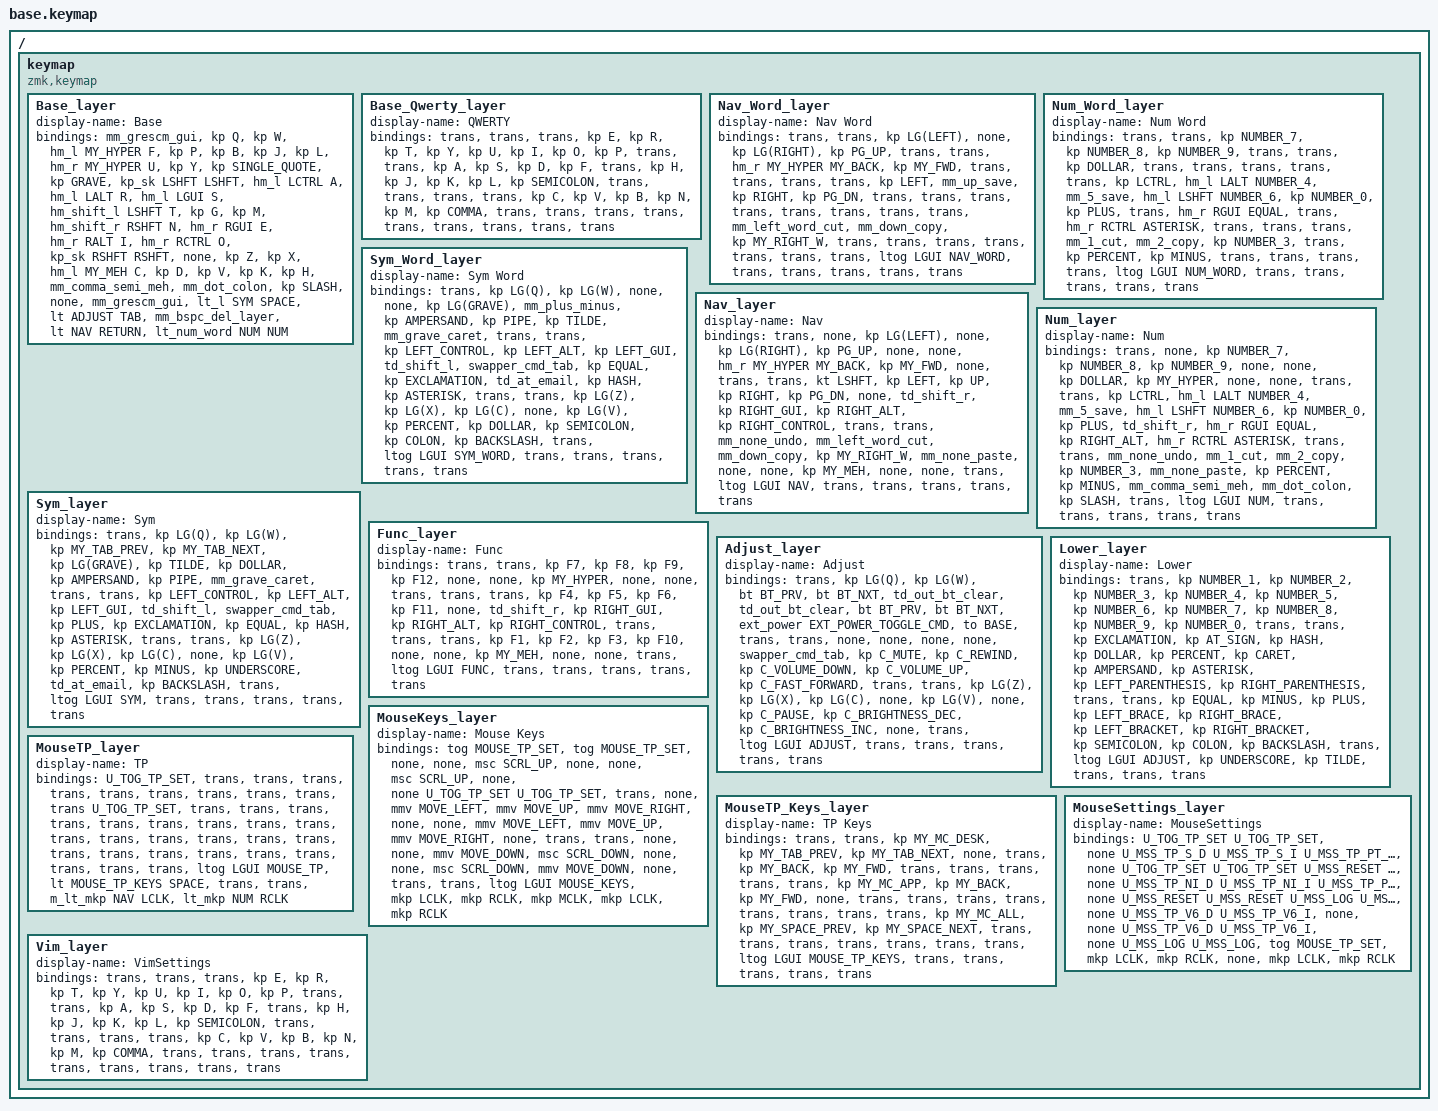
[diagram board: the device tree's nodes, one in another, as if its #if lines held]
/*
 * Copyright (c) 2020 The ZMK Contributors
 *
 * SPDX-License-Identifier: MIT
 */

// Define layer numbers
#define BASE 0
#define BASE_QWERTY 1
#define NAV_WORD 2
#define NUM_WORD 3
#define SYM_WORD 4
#define NAV 5
#define NUM 6
#define SYM 7
#define FUNC 8
#define ADJUST 9
#define LOWER 10
#define MOUSE_KEYS 11
#define MOUSE_TP 12
#define MOUSE_TP_KEYS 13
#define MOUSE_TP_SET 14
#define VIM 15

#ifdef HAS_UROB
  #define HAS_TRI_STATE
  #define HAS_NUM_WORD
#endif

// ZMK includes
#include <behaviors.dtsi>
#include <dt-bindings/zmk/keys.h>
#include <dt-bindings/zmk/bt.h>
#include <dt-bindings/zmk/rgb.h>
#include <dt-bindings/zmk/ext_power.h>


// Personal includes
#include "includes/custom_keycodes.dtsi"
#include "includes/settings.dtsi"
//#include "includes/settings_pd.dtsi"
#include "includes/conditional_layers.dtsi"
#include "includes/macros.dtsi"
#include "includes/combos.dtsi"
#include "includes/behaviours_homerow_mods.dtsi"
#include "includes/behaviours_mod_morph.dtsi"
#include "includes/behaviours_other.dtsi"
#include "includes/mouse_keys.dtsi"
#include "includes/mouse_tp.dtsi"
#include "includes/mouse_tp_badjeff_input_listener.dtsi"


#ifdef HAS_MOUSE_TP
  #define U_TOG_TP_SET &tog MOUSE_TP_SET
#else
  #define U_TOG_TP_SET &none
#endif  // HAS_MOUSE_TP


/ {

  keymap {
    compatible = "zmk,keymap";

    Base_layer {
      display-name = "Base";
      bindings = <
// ╭────────────────────────┬────────────────────────┬────────────────────────┬────────────────────────┬────────────────────────┬────────────────────────╮    ╭────────────────────────┬────────────────────────┬────────────────────────┬───────────────────────┬────────────────────────┬────────────────────────╮
     &mm_grescm_gui           &kp Q                    &kp W                    &hm_l MY_HYPER F         &kp P                    &kp B                         &kp J                    &kp L                    &hm_r MY_HYPER U         &kp Y                    &kp SINGLE_QUOTE         &kp GRAVE
// ├────────────────────────┼────────────────────────┼────────────────────────┼────────────────────────┼────────────────────────┼────────────────────────┤    ├────────────────────────┼────────────────────────┼────────────────────────┼───────────────────────┼────────────────────────┼────────────────────────┤
     &kp_sk LSHFT LSHFT       &hm_l LCTRL A            &hm_l LALT R             &hm_l LGUI S             &hm_shift_l LSHFT T      &kp G                         &kp M                    &hm_shift_r RSHFT N      &hm_r RGUI E             &hm_r RALT I             &hm_r RCTRL O            &kp_sk RSHFT RSHFT
// ├────────────────────────┼────────────────────────┼────────────────────────┼────────────────────────┼────────────────────────┼────────────────────────┤    ├────────────────────────┼────────────────────────┼────────────────────────┼───────────────────────┼────────────────────────┼────────────────────────┤
     &none                    &kp Z                    &kp X                    &hm_l MY_MEH C           &kp D                    &kp V                         &kp K                    &kp H                    &mm_comma_semi_meh       &mm_dot_colon            &kp SLASH                &none
// ╰────────────────────────┴────────────────────────┴────────────────────────┴────────────────────────┼────────────────────────┼────────────────────────┤    ├────────────────────────┼────────────────────────┼────────────────────────┼───────────────────────┼────────────────────────┼────────────────────────╯
                                                                                &mm_grescm_gui           &lt_l SYM SPACE          &lt ADJUST TAB                &mm_bspc_del_layer       &lt NAV RETURN           &lt_num_word NUM NUM
//                                                                            ╰────────────────────────┴────────────────────────┴────────────────────────╯    ╰────────────────────────┴────────────────────────┴────────────────────────╯

      >;
     //  sensor-bindings = <&inc_dec_kp C_VOL_DN C_VOL_UP &inc_dec_kp C_PREV C_NEXT>;
    };

    Base_Qwerty_layer {
      display-name = "QWERTY";
      bindings = <
// ╭────────────────────────┬────────────────────────┬────────────────────────┬────────────────────────┬────────────────────────┬────────────────────────╮    ╭────────────────────────┬────────────────────────┬────────────────────────┬────────────────────────┬────────────────────────┬────────────────────────╮
     &trans                   &trans                   &trans                   &kp E                    &kp R                    &kp T                         &kp Y                    &kp U                    &kp I                    &kp O                    &kp P                     &trans
// ├────────────────────────┼────────────────────────┼────────────────────────┼────────────────────────┼────────────────────────┼────────────────────────┤    ├────────────────────────┼────────────────────────┼────────────────────────┼────────────────────────┼────────────────────────┼────────────────────────┤
     &trans                   &kp A                    &kp S                    &kp D                    &kp F                    &trans                        &kp H                    &kp J                    &kp K                    &kp L                    &kp SEMICOLON             &trans
// ├────────────────────────┼────────────────────────┼────────────────────────┼────────────────────────┼────────────────────────┼────────────────────────┤    ├────────────────────────┼────────────────────────┼────────────────────────┼────────────────────────┼────────────────────────┼────────────────────────┤
     &trans                   &trans                   &trans                   &kp C                    &kp V                    &kp B                         &kp N                    &kp M                    &kp COMMA                &trans                   &trans                    &trans
// ╰────────────────────────┴────────────────────────┴────────────────────────┴────────────────────────┼────────────────────────┼────────────────────────┤    ├────────────────────────┼────────────────────────┼────────────────────────┼────────────────────────┴────────────────────────┼────────────────────────╯
                                                                                &trans                   &trans                   &trans                        &trans                   &trans                   &trans
//                                                                            ╰────────────────────────┴────────────────────────┴────────────────────────╯    ╰────────────────────────┴────────────────────────┴────────────────────────╯
      >;
    };

    Nav_Word_layer {
      display-name = "Nav Word";
      bindings = <
// ╭────────────────────────┬────────────────────────┬────────────────────────┬────────────────────────┬────────────────────────┬────────────────────────╮    ╭────────────────────────┬────────────────────────┬────────────────────────┬────────────────────────┬────────────────────────┬────────────────────────╮
     &trans                   &trans                   &kp LG(LEFT)             &none                    &kp LG(RIGHT)            &kp PG_UP                     &trans                   &trans                   &hm_r MY_HYPER MY_BACK   &kp MY_FWD               &trans                    &trans
// ├────────────────────────┼────────────────────────┼────────────────────────┼────────────────────────┼────────────────────────┼────────────────────────┤    ├────────────────────────┼────────────────────────┼────────────────────────┼────────────────────────┼────────────────────────┼────────────────────────┤
     &trans                   &trans                   &kp LEFT                 &mm_up_save              &kp RIGHT                &kp PG_DN                     &trans                   &trans                   &trans                   &trans                   &trans                    &trans
// ├────────────────────────┼────────────────────────┼────────────────────────┼────────────────────────┼────────────────────────┼────────────────────────┤    ├────────────────────────┼────────────────────────┼────────────────────────┼────────────────────────┼────────────────────────┼────────────────────────┤
     &trans                   &trans                   &mm_left_word_cut        &mm_down_copy            &kp MY_RIGHT_W           &trans                        &trans                   &trans                   &trans                   &trans                   &trans                    &trans
// ╰────────────────────────┴────────────────────────┴────────────────────────┴────────────────────────┼────────────────────────┼────────────────────────┤    ├────────────────────────┼────────────────────────┼────────────────────────┼────────────────────────┴────────────────────────┼────────────────────────╯
                                                                                &ltog LGUI NAV_WORD      &trans                   &trans                        &trans                   &trans                   &trans
//                                                                            ╰────────────────────────┴────────────────────────┴────────────────────────╯    ╰────────────────────────┴────────────────────────┴────────────────────────╯
      >;
     //  sensor-bindings = <&inc_dec_kp C_BRI_DN C_BRI_UP &inc_dec_kp LEFT RIGHT>;
    };

    Num_Word_layer {
      display-name = "Num Word";
      bindings = <
// ╭────────────────────────┬────────────────────────┬────────────────────────┬────────────────────────┬────────────────────────┬────────────────────────╮    ╭────────────────────────┬────────────────────────┬────────────────────────┬────────────────────────┬────────────────────────┬────────────────────────╮
     &trans                   &trans                   &kp NUMBER_7             &kp NUMBER_8             &kp NUMBER_9             &trans                        &trans                   &kp DOLLAR               &trans                   &trans                   &trans                    &trans
// ├────────────────────────┼────────────────────────┼────────────────────────┼────────────────────────┼────────────────────────┼────────────────────────┤    ├────────────────────────┼────────────────────────┼────────────────────────┼────────────────────────┼────────────────────────┼────────────────────────┤
     &trans                   &kp LCTRL                &hm_l LALT NUMBER_4      &mm_5_save               &hm_l LSHFT NUMBER_6     &kp NUMBER_0                  &kp PLUS                 &trans                   &hm_r RGUI EQUAL         &trans                   &hm_r RCTRL ASTERISK      &trans
// ├────────────────────────┼────────────────────────┼────────────────────────┼────────────────────────┼────────────────────────┼────────────────────────┤    ├────────────────────────┼────────────────────────┼────────────────────────┼────────────────────────┼────────────────────────┼────────────────────────┤
     &trans                   &trans                   &mm_1_cut                &mm_2_copy               &kp NUMBER_3             &trans                        &kp PERCENT              &kp MINUS                &trans                   &trans                   &trans                    &trans
// ╰────────────────────────┴────────────────────────┴────────────────────────┴────────────────────────┼────────────────────────┼────────────────────────┤    ├────────────────────────┼────────────────────────┼────────────────────────┼────────────────────────┴────────────────────────┼────────────────────────╯
                                                                                &ltog LGUI NUM_WORD      &trans                   &trans                        &trans                   &trans                   &trans
//                                                                            ╰────────────────────────┴────────────────────────┴────────────────────────╯    ╰────────────────────────┴────────────────────────┴────────────────────────╯
      >;
     //  sensor-bindings = <&inc_dec_kp C_BRI_DN C_BRI_UP &inc_dec_kp LEFT RIGHT>;
    };

    Sym_Word_layer {
      display-name = "Sym Word";
      bindings = <
// ╭────────────────────────┬────────────────────────┬────────────────────────┬────────────────────────┬────────────────────────┬────────────────────────╮    ╭────────────────────────┬────────────────────────┬────────────────────────┬────────────────────────┬────────────────────────┬────────────────────────╮
     &trans                   &kp LG(Q)                &kp LG(W)                &none                    &none                    &kp LG(GRAVE)                 &mm_plus_minus           &kp AMPERSAND            &kp PIPE                 &kp TILDE                &mm_grave_caret           &trans
// ├────────────────────────┼────────────────────────┼────────────────────────┼────────────────────────┼────────────────────────┼────────────────────────┤    ├────────────────────────┼────────────────────────┼────────────────────────┼────────────────────────┼────────────────────────┼────────────────────────┤
     &trans                   &kp LEFT_CONTROL         &kp LEFT_ALT             &kp LEFT_GUI             &td_shift_l              &swapper_cmd_tab              &kp EQUAL                &kp EXCLAMATION          &td_at_email             &kp HASH                 &kp ASTERISK              &trans
// ├────────────────────────┼────────────────────────┼────────────────────────┼────────────────────────┼────────────────────────┼────────────────────────┤    ├────────────────────────┼────────────────────────┼────────────────────────┼────────────────────────┼────────────────────────┼────────────────────────┤
     &trans                   &kp LG(Z)                &kp LG(X)                &kp LG(C)                &none                    &kp LG(V)                     &kp PERCENT              &kp DOLLAR               &kp SEMICOLON            &kp COLON                &kp BACKSLASH             &trans
// ╰────────────────────────┴────────────────────────┴────────────────────────┴────────────────────────┼────────────────────────┼────────────────────────┤    ├────────────────────────┼────────────────────────┼────────────────────────┼────────────────────────┴────────────────────────┼────────────────────────╯
                                                                                &ltog LGUI SYM_WORD      &trans                   &trans                        &trans                   &trans                   &trans
//                                                                            ╰────────────────────────┴────────────────────────┴────────────────────────╯    ╰────────────────────────┴────────────────────────┴────────────────────────╯
      >;
     //  sensor-bindings = <&inc_dec_kp C_BRI_DN C_BRI_UP &inc_dec_kp LEFT RIGHT>;
    };

    Nav_layer {
      display-name = "Nav";
      bindings = <
// ╭────────────────────────┬────────────────────────┬────────────────────────┬────────────────────────┬────────────────────────┬────────────────────────╮    ╭────────────────────────┬────────────────────────┬────────────────────────┬────────────────────────┬────────────────────────┬────────────────────────╮
     &trans                   &none                    &kp LG(LEFT)             &none                    &kp LG(RIGHT)            &kp PG_UP                     &none                    &none                    &hm_r MY_HYPER MY_BACK   &kp MY_FWD               &none                     &trans
// ├────────────────────────┼────────────────────────┼────────────────────────┼────────────────────────┼────────────────────────┼────────────────────────┤    ├────────────────────────┼────────────────────────┼────────────────────────┼────────────────────────┼────────────────────────┼────────────────────────┤
     &trans                   &kt LSHFT                &kp LEFT                 &kp UP                   &kp RIGHT                &kp PG_DN                     &none                    &td_shift_r              &kp RIGHT_GUI            &kp RIGHT_ALT            &kp RIGHT_CONTROL         &trans
// ├────────────────────────┼────────────────────────┼────────────────────────┼────────────────────────┼────────────────────────┼────────────────────────┤    ├────────────────────────┼────────────────────────┼────────────────────────┼────────────────────────┼────────────────────────┼────────────────────────┤
     &trans                   &mm_none_undo            &mm_left_word_cut        &mm_down_copy            &kp MY_RIGHT_W           &mm_none_paste                &none                    &none                    &kp MY_MEH               &none                    &none                     &trans
// ╰────────────────────────┴────────────────────────┴────────────────────────┴────────────────────────┼────────────────────────┼────────────────────────┤    ├────────────────────────┼────────────────────────┼────────────────────────┼────────────────────────┴────────────────────────┼────────────────────────╯
                                                                                &ltog LGUI NAV           &trans                   &trans                        &trans                   &trans                   &trans
//                                                                            ╰────────────────────────┴────────────────────────┴────────────────────────╯    ╰────────────────────────┴────────────────────────┴────────────────────────╯
      >;
     //  sensor-bindings = <&inc_dec_kp C_BRI_DN C_BRI_UP &inc_dec_kp LEFT RIGHT>;
    };

    Num_layer {
      display-name = "Num";
      bindings = <
// ╭────────────────────────┬────────────────────────┬────────────────────────┬────────────────────────┬────────────────────────┬────────────────────────╮    ╭────────────────────────┬────────────────────────┬────────────────────────┬────────────────────────┬────────────────────────┬────────────────────────╮
     &trans                   &none                    &kp NUMBER_7             &kp NUMBER_8             &kp NUMBER_9             &none                         &none                    &kp DOLLAR               &kp MY_HYPER             &none                    &none                     &trans
// ├────────────────────────┼────────────────────────┼────────────────────────┼────────────────────────┼────────────────────────┼────────────────────────┤    ├────────────────────────┼────────────────────────┼────────────────────────┼────────────────────────┼────────────────────────┼────────────────────────┤
     &trans                   &kp LCTRL                &hm_l LALT NUMBER_4      &mm_5_save               &hm_l LSHFT NUMBER_6     &kp NUMBER_0                  &kp PLUS                 &td_shift_r              &hm_r RGUI EQUAL         &kp RIGHT_ALT            &hm_r RCTRL ASTERISK      &trans
// ├────────────────────────┼────────────────────────┼────────────────────────┼────────────────────────┼────────────────────────┼────────────────────────┤    ├────────────────────────┼────────────────────────┼────────────────────────┼────────────────────────┼────────────────────────┼────────────────────────┤
     &trans                   &mm_none_undo            &mm_1_cut                &mm_2_copy               &kp NUMBER_3             &mm_none_paste                &kp PERCENT              &kp MINUS                &mm_comma_semi_meh       &mm_dot_colon            &kp SLASH                 &trans
// ╰────────────────────────┴────────────────────────┴────────────────────────┴────────────────────────┼────────────────────────┼────────────────────────┤    ├────────────────────────┼────────────────────────┼────────────────────────┼────────────────────────┴────────────────────────┼────────────────────────╯
                                                                                &ltog LGUI NUM           &trans                   &trans                        &trans                   &trans                   &trans
//                                                                            ╰────────────────────────┴────────────────────────┴────────────────────────╯    ╰────────────────────────┴────────────────────────┴────────────────────────╯
      >;
     //  sensor-bindings = <&inc_dec_kp C_BRI_DN C_BRI_UP &inc_dec_kp LEFT RIGHT>;
    };

    Sym_layer {
      display-name = "Sym";
      bindings = <
// ╭────────────────────────┬────────────────────────┬────────────────────────┬────────────────────────┬────────────────────────┬────────────────────────╮    ╭────────────────────────┬────────────────────────┬────────────────────────┬────────────────────────┬────────────────────────┬────────────────────────╮
     &trans                   &kp LG(Q)                &kp LG(W)                &kp MY_TAB_PREV          &kp MY_TAB_NEXT          &kp LG(GRAVE)                 &kp TILDE                &kp DOLLAR               &kp AMPERSAND            &kp PIPE                 &mm_grave_caret           &trans
// ├────────────────────────┼────────────────────────┼────────────────────────┼────────────────────────┼────────────────────────┼────────────────────────┤    ├────────────────────────┼────────────────────────┼────────────────────────┼────────────────────────┼────────────────────────┼────────────────────────┤
     &trans                   &kp LEFT_CONTROL         &kp LEFT_ALT             &kp LEFT_GUI             &td_shift_l              &swapper_cmd_tab              &kp PLUS                 &kp EXCLAMATION          &kp EQUAL                &kp HASH                 &kp ASTERISK              &trans
// ├────────────────────────┼────────────────────────┼────────────────────────┼────────────────────────┼────────────────────────┼────────────────────────┤    ├────────────────────────┼────────────────────────┼────────────────────────┼────────────────────────┼────────────────────────┼────────────────────────┤
     &trans                   &kp LG(Z)                &kp LG(X)                &kp LG(C)                &none &kp                LG(V)                         &kp PERCENT              &kp MINUS                &kp UNDERSCORE           &td_at_email             &kp BACKSLASH             &trans
// ╰────────────────────────┴────────────────────────┴────────────────────────┴────────────────────────┼────────────────────────┼────────────────────────┤    ├────────────────────────┼────────────────────────┼────────────────────────┼────────────────────────┴────────────────────────┼────────────────────────╯
                                                                                &ltog LGUI SYM           &trans                   &trans                        &trans                   &trans                   &trans
//                                                                            ╰────────────────────────┴────────────────────────┴────────────────────────╯    ╰────────────────────────┴────────────────────────┴────────────────────────╯
      >;
     //  sensor-bindings = <&inc_dec_kp C_BRI_DN C_BRI_UP &inc_dec_kp LEFT RIGHT>;
    };

    Func_layer {
      display-name = "Func";
      bindings = <
// ╭────────────────────────┬────────────────────────┬────────────────────────┬────────────────────────┬────────────────────────┬────────────────────────╮    ╭────────────────────────┬────────────────────────┬────────────────────────┬────────────────────────┬────────────────────────┬────────────────────────╮
     &trans                   &trans                   &kp F7                   &kp F8                   &kp F9                   &kp F12                       &none                    &none                    &kp MY_HYPER             &none                    &none                     &trans
// ├────────────────────────┼────────────────────────┼────────────────────────┼────────────────────────┼────────────────────────┼────────────────────────┤    ├────────────────────────┼────────────────────────┼────────────────────────┼────────────────────────┼────────────────────────┼────────────────────────┤
     &trans                   &trans                   &kp F4                   &kp F5                   &kp F6                   &kp F11                       &none                    &td_shift_r              &kp RIGHT_GUI            &kp RIGHT_ALT            &kp RIGHT_CONTROL         &trans
// ├────────────────────────┼────────────────────────┼────────────────────────┼────────────────────────┼────────────────────────┼────────────────────────┤    ├────────────────────────┼────────────────────────┼────────────────────────┼────────────────────────┼────────────────────────┼────────────────────────┤
     &trans                   &trans                   &kp F1                   &kp F2                   &kp F3                   &kp F10                       &none                    &none                    &kp MY_MEH               &none                    &none                     &trans
// ╰────────────────────────┴────────────────────────┴────────────────────────┴────────────────────────┼────────────────────────┼────────────────────────┤    ├────────────────────────┼────────────────────────┼────────────────────────┼────────────────────────┴────────────────────────┼────────────────────────╯
                                                                                &ltog LGUI FUNC          &trans                   &trans                        &trans                   &trans                   &trans
//                                                                            ╰────────────────────────┴────────────────────────┴────────────────────────╯    ╰────────────────────────┴────────────────────────┴────────────────────────╯
      >;
     //  sensor-bindings = <&inc_dec_kp C_BRI_DN C_BRI_UP &inc_dec_kp LEFT RIGHT>;
    };

    Adjust_layer {
      display-name = "Adjust";
      bindings = <
// ╭────────────────────────┬────────────────────────┬────────────────────────┬────────────────────────┬────────────────────────┬────────────────────────╮    ╭────────────────────────┬────────────────────────┬────────────────────────┬────────────────────────┬────────────────────────┬────────────────────────╮
     &trans                   &kp LG(Q)                &kp LG(W)                &bt BT_PRV               &bt BT_NXT               &td_out_bt_clear              &td_out_bt_clear         &bt BT_PRV               &bt BT_NXT               &ext_power EXT_POWER_TOGGLE_CMD &to BASE           &trans
// ├────────────────────────┼────────────────────────┼────────────────────────┼────────────────────────┼────────────────────────┼────────────────────────┤    ├────────────────────────┼────────────────────────┼────────────────────────┼────────────────────────┼────────────────────────┼────────────────────────┤
     &trans                   &none                    &none                    &none                    &none                    &swapper_cmd_tab              &kp C_MUTE               &kp C_REWIND             &kp C_VOLUME_DOWN        &kp C_VOLUME_UP          &kp C_FAST_FORWARD        &trans
// ├────────────────────────┼────────────────────────┼────────────────────────┼────────────────────────┼────────────────────────┼────────────────────────┤    ├────────────────────────┼────────────────────────┼────────────────────────┼────────────────────────┼────────────────────────┼────────────────────────┤
     &trans                   &kp LG(Z)                &kp LG(X)                &kp LG(C)                &none                    &kp LG(V)                     &none                    &kp C_PAUSE              &kp C_BRIGHTNESS_DEC     &kp C_BRIGHTNESS_INC     &none                     &trans
// ╰────────────────────────┴────────────────────────┴────────────────────────┴────────────────────────┼────────────────────────┼────────────────────────┤    ├────────────────────────┼────────────────────────┼────────────────────────┼────────────────────────┴────────────────────────┼────────────────────────╯
                                                                                &ltog LGUI ADJUST        &trans                   &trans                        &trans                   &trans                   &trans
//                                                                            ╰────────────────────────┴────────────────────────┴────────────────────────╯    ╰────────────────────────┴────────────────────────┴────────────────────────╯
      >;
     //  sensor-bindings = <&inc_dec_kp C_BRI_DN C_BRI_UP &inc_dec_kp LEFT RIGHT>;
    };

    Lower_layer {
      display-name = "Lower";
      bindings = <
// ╭────────────────────────┬────────────────────────┬────────────────────────┬────────────────────────┬────────────────────────┬────────────────────────╮    ╭────────────────────────┬────────────────────────┬────────────────────────┬────────────────────────┬────────────────────────┬────────────────────────╮
     &trans                   &kp NUMBER_1             &kp NUMBER_2             &kp NUMBER_3             &kp NUMBER_4             &kp NUMBER_5                  &kp NUMBER_6             &kp NUMBER_7             &kp NUMBER_8             &kp NUMBER_9             &kp NUMBER_0              &trans
// ├────────────────────────┼────────────────────────┼────────────────────────┼────────────────────────┼────────────────────────┼────────────────────────┤    ├────────────────────────┼────────────────────────┼────────────────────────┼────────────────────────┼────────────────────────┼────────────────────────┤
     &trans                   &kp EXCLAMATION          &kp AT_SIGN              &kp HASH                 &kp DOLLAR               &kp PERCENT                   &kp CARET                &kp AMPERSAND            &kp ASTERISK             &kp LEFT_PARENTHESIS     &kp RIGHT_PARENTHESIS     &trans
// ├────────────────────────┼────────────────────────┼────────────────────────┼────────────────────────┼────────────────────────┼────────────────────────┤    ├────────────────────────┼────────────────────────┼────────────────────────┼────────────────────────┼────────────────────────┼────────────────────────┤
     &trans                   &kp EQUAL                &kp MINUS                &kp PLUS                 &kp LEFT_BRACE           &kp RIGHT_BRACE               &kp LEFT_BRACKET         &kp RIGHT_BRACKET        &kp SEMICOLON            &kp COLON                &kp BACKSLASH             &trans
// ╰────────────────────────┴────────────────────────┴────────────────────────┴────────────────────────┼────────────────────────┼────────────────────────┤    ├────────────────────────┼────────────────────────┼────────────────────────┼────────────────────────┴────────────────────────┼────────────────────────╯
                                                                                &ltog LGUI ADJUST        &kp UNDERSCORE           &kp TILDE                     &trans                    &trans                  &trans
//                                                                            ╰────────────────────────┴────────────────────────┴────────────────────────╯    ╰────────────────────────┴────────────────────────┴────────────────────────╯
      >;
     //  sensor-bindings = <&inc_dec_kp C_BRI_DN C_BRI_UP &inc_dec_kp LEFT RIGHT>;
    };

#ifdef HAS_MOUSE_KEYS
    MouseKeys_layer {
      display-name = "Mouse Keys";
      bindings = <
// ╭────────────────────────┬────────────────────────┬────────────────────────┬────────────────────────┬────────────────────────┬────────────────────────╮    ╭────────────────────────┬────────────────────────┬────────────────────────┬────────────────────────┬────────────────────────┬────────────────────────╮
     &tog MOUSE_TP_SET        &tog MOUSE_TP_SET        &none                    &none                    &msc SCRL_UP             &none                         &none                    &msc SCRL_UP             &none                    &none                    U_TOG_TP_SET             U_TOG_TP_SET
// ├────────────────────────┼────────────────────────┼────────────────────────┼────────────────────────┼────────────────────────┼────────────────────────┤    ├────────────────────────┼────────────────────────┼────────────────────────┼────────────────────────┼────────────────────────┼────────────────────────┤
     &trans                   &none                    &mmv MOVE_LEFT           &mmv MOVE_UP             &mmv MOVE_RIGHT          &none                         &none                    &mmv MOVE_LEFT           &mmv MOVE_UP             &mmv MOVE_RIGHT          &none                     &trans
// ├────────────────────────┼────────────────────────┼────────────────────────┼────────────────────────┼────────────────────────┼────────────────────────┤    ├────────────────────────┼────────────────────────┼────────────────────────┼────────────────────────┼────────────────────────┼────────────────────────┤
     &trans                   &none                    &none                    &mmv MOVE_DOWN           &msc SCRL_DOWN           &none                         &none                    &msc SCRL_DOWN           &mmv MOVE_DOWN           &none                    &trans                    &trans
// ╰────────────────────────┴────────────────────────┴────────────────────────┴────────────────────────┼────────────────────────┼────────────────────────┤    ├────────────────────────┼────────────────────────┼────────────────────────┼────────────────────────┴────────────────────────┼────────────────────────╯
                                                                                &ltog LGUI MOUSE_KEYS    &mkp LCLK                &mkp RCLK                     &mkp MCLK                &mkp LCLK                &mkp RCLK
//                                                                            ╰────────────────────────┴────────────────────────┴────────────────────────╯    ╰────────────────────────┴────────────────────────┴────────────────────────╯
      >;
     //  sensor-bindings = <&inc_dec_kp C_BRI_DN C_BRI_UP &inc_dec_kp LEFT RIGHT>;
    };
#endif

#ifdef HAS_MOUSE_TP
    MouseTP_layer {
      display-name = "TP";
      bindings = <
// ╭────────────────────────┬────────────────────────┬────────────────────────┬────────────────────────┬────────────────────────┬────────────────────────╮    ╭────────────────────────┬────────────────────────┬────────────────────────┬────────────────────────┬────────────────────────┬────────────────────────╮
     U_TOG_TP_SET             &trans                   &trans                   &trans                   &trans                   &trans                        &trans                   &trans                   &trans                    &trans                   &trans                    U_TOG_TP_SET
// ├────────────────────────┼────────────────────────┼────────────────────────┼────────────────────────┼────────────────────────┼────────────────────────┤    ├────────────────────────┼────────────────────────┼────────────────────────┼────────────────────────┼────────────────────────┼────────────────────────┤
     &trans                   &trans                   &trans                   &trans                   &trans                   &trans                        &trans                   &trans                   &trans                    &trans                   &trans                    &trans
// ├────────────────────────┼────────────────────────┼────────────────────────┼────────────────────────┼────────────────────────┼────────────────────────┤    ├────────────────────────┼────────────────────────┼────────────────────────┼────────────────────────┼────────────────────────┼────────────────────────┤
     &trans                   &trans                   &trans                   &trans                   &trans                   &trans                        &trans                   &trans                   &trans                    &trans                   &trans                    &trans
// ╰────────────────────────┴────────────────────────┴────────────────────────┴────────────────────────┼────────────────────────┼────────────────────────┤    ├────────────────────────┼────────────────────────┼────────────────────────┼────────────────────────┴────────────────────────┼────────────────────────╯
                                                                                &ltog LGUI MOUSE_TP      &lt MOUSE_TP_KEYS SPACE  &trans                        &trans                    &m_lt_mkp NAV LCLK      &lt_mkp NUM RCLK
//                                                                            ╰────────────────────────┴────────────────────────┴────────────────────────╯    ╰────────────────────────┴────────────────────────┴────────────────────────╯
      >;
     //  sensor-bindings = <&inc_dec_kp C_BRI_DN C_BRI_UP &inc_dec_kp LEFT RIGHT>;
    };

    MouseTP_Keys_layer {
      display-name = "TP Keys";
      bindings = <
// ╭────────────────────────┬────────────────────────┬────────────────────────┬────────────────────────┬────────────────────────┬────────────────────────╮    ╭────────────────────────┬────────────────────────┬────────────────────────┬────────────────────────┬────────────────────────┬────────────────────────╮
     &trans                   &trans                   &kp MY_MC_DESK           &kp MY_TAB_PREV          &kp MY_TAB_NEXT          &none                         &trans                   &kp MY_BACK               &kp MY_FWD               &trans                    &trans                  &trans
// ├────────────────────────┼────────────────────────┼────────────────────────┼────────────────────────┼────────────────────────┼────────────────────────┤    ├────────────────────────┼────────────────────────┼────────────────────────┼────────────────────────┼────────────────────────┼────────────────────────┤
     &trans                   &trans                   &kp MY_MC_APP            &kp MY_BACK              &kp MY_FWD               &none                         &trans                   &trans                    &trans                   &trans                    &trans                  &trans
// ├────────────────────────┼────────────────────────┼────────────────────────┼────────────────────────┼────────────────────────┼────────────────────────┤    ├────────────────────────┼────────────────────────┼────────────────────────┼────────────────────────┼────────────────────────┼────────────────────────┤
     &trans                   &trans                   &kp MY_MC_ALL            &kp MY_SPACE_PREV        &kp MY_SPACE_NEXT        &trans                        &trans                   &trans                    &trans                   &trans                    &trans                  &trans
// ╰────────────────────────┴────────────────────────┴────────────────────────┴────────────────────────┼────────────────────────┼────────────────────────┤    ├────────────────────────┼────────────────────────┼────────────────────────┼────────────────────────┴────────────────────────┼────────────────────────╯
                                                                                &ltog LGUI MOUSE_TP_KEYS &trans                   &trans                        &trans                    &trans                   &trans
//                                                                            ╰────────────────────────┴────────────────────────┴────────────────────────╯    ╰────────────────────────┴────────────────────────┴────────────────────────╯
      >;
     //  sensor-bindings = <&inc_dec_kp C_BRI_DN C_BRI_UP &inc_dec_kp LEFT RIGHT>;
    };

    MouseSettings_layer {
      display-name = "MouseSettings";
      bindings = <
// ╭────────────────────────┬────────────────────────┬────────────────────────┬────────────────────────┬────────────────────────┬────────────────────────╮    ╭────────────────────────┬────────────────────────┬────────────────────────┬────────────────────────┬────────────────────────┬────────────────────────╮
     U_TOG_TP_SET             U_TOG_TP_SET             &none                    U_MSS_TP_S_D             U_MSS_TP_S_I             U_MSS_TP_PT_I                 U_MSS_TP_PT_I            U_MSS_TP_S_D             U_MSS_TP_S_I             &none                    U_TOG_TP_SET             U_TOG_TP_SET
// ├────────────────────────┼────────────────────────┼────────────────────────┼────────────────────────┼────────────────────────┼────────────────────────┤    ├────────────────────────┼────────────────────────┼────────────────────────┼────────────────────────┼────────────────────────┼────────────────────────┤
     U_MSS_RESET              U_MSS_RESET              &none                    U_MSS_TP_NI_D            U_MSS_TP_NI_I            U_MSS_TP_PT_D                 U_MSS_TP_PT_D            U_MSS_TP_NI_D            U_MSS_TP_NI_I            &none                    U_MSS_RESET               U_MSS_RESET
// ├────────────────────────┼────────────────────────┼────────────────────────┼────────────────────────┼────────────────────────┼────────────────────────┤    ├────────────────────────┼────────────────────────┼────────────────────────┼────────────────────────┼────────────────────────┼────────────────────────┤
     U_MSS_LOG                U_MSS_LOG                &none                    U_MSS_TP_V6_D            U_MSS_TP_V6_I            &none                         &none                    U_MSS_TP_V6_D            U_MSS_TP_V6_I            &none                    U_MSS_LOG                 U_MSS_LOG
// ╰────────────────────────┴────────────────────────┴────────────────────────┴────────────────────────┼────────────────────────┼────────────────────────┤    ├────────────────────────┼────────────────────────┼────────────────────────┼────────────────────────┴────────────────────────┼────────────────────────╯
                                                                                &tog MOUSE_TP_SET        &mkp LCLK                &mkp RCLK                     &none                    &mkp LCLK                &mkp RCLK
//                                                                            ╰────────────────────────┴────────────────────────┴────────────────────────╯    ╰────────────────────────┴────────────────────────┴────────────────────────╯
      >;
     //  sensor-bindings = <&inc_dec_kp C_BRI_DN C_BRI_UP &inc_dec_kp LEFT RIGHT>;
    };
#endif

    Vim_layer {
      display-name = "VimSettings";
      bindings = <
// ╭────────────────────────┬────────────────────────┬────────────────────────┬────────────────────────┬────────────────────────┬────────────────────────╮    ╭────────────────────────┬────────────────────────┬────────────────────────┬────────────────────────┬────────────────────────┬────────────────────────╮
     &trans                   &trans                   &trans                   &kp E                    &kp R                    &kp T                         &kp Y                    &kp U                    &kp I                    &kp O                    &kp P                     &trans
// ├────────────────────────┼────────────────────────┼────────────────────────┼────────────────────────┼────────────────────────┼────────────────────────┤    ├────────────────────────┼────────────────────────┼────────────────────────┼────────────────────────┼────────────────────────┼────────────────────────┤
     &trans                   &kp A                    &kp S                    &kp D                    &kp F                    &trans                        &kp H                    &kp J                    &kp K                    &kp L                    &kp SEMICOLON             &trans
// ├────────────────────────┼────────────────────────┼────────────────────────┼────────────────────────┼────────────────────────┼────────────────────────┤    ├────────────────────────┼────────────────────────┼────────────────────────┼────────────────────────┼────────────────────────┼────────────────────────┤
     &trans                   &trans                   &trans                   &kp C                    &kp V                    &kp B                         &kp N                    &kp M                    &kp COMMA                &trans                   &trans                    &trans
// ╰────────────────────────┴────────────────────────┴────────────────────────┴────────────────────────┼────────────────────────┼────────────────────────┤    ├────────────────────────┼────────────────────────┼────────────────────────┼────────────────────────┴────────────────────────┼────────────────────────╯
                                                                                &trans                   &trans                   &trans                        &trans                   &trans                   &trans
//                                                                            ╰────────────────────────┴────────────────────────┴────────────────────────╯    ╰────────────────────────┴────────────────────────┴────────────────────────╯
      >;
     //  Vim-bindings = <&inc_dec_kp C_BRI_DN C_BRI_UP &inc_dec_kp LEFT RIGHT>;
    };

  };

};
